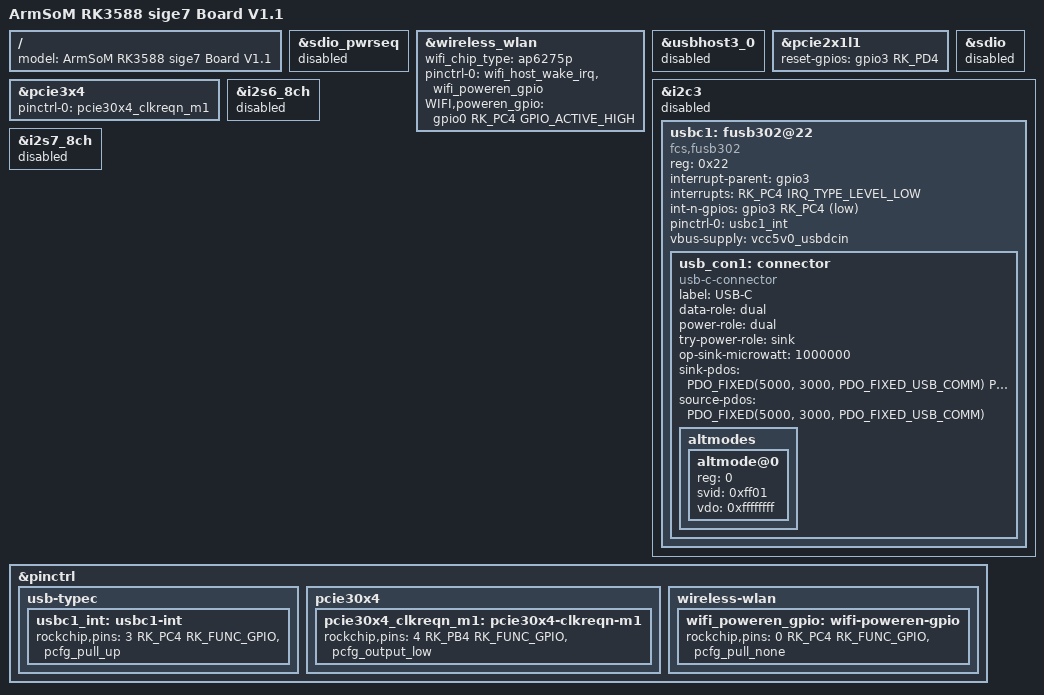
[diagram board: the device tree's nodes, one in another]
/dts-v1/;

#include "rk3588-sige7-v1.dts"

/ {
	model = "ArmSoM RK3588 sige7 Board V1.1";
};

&sdio_pwrseq {
	status = "disabled";
};

&wireless_wlan {
	wifi_chip_type = "ap6275p";
	pinctrl-0 = <&wifi_host_wake_irq>, <&wifi_poweren_gpio>;
	WIFI,poweren_gpio = <&gpio0 RK_PC4 GPIO_ACTIVE_HIGH>;
};

// combphy2_psu mux to pcie2x1l1
&usbhost3_0 {
	status = "disabled";
};

&pcie2x1l1 {
	reset-gpios = <&gpio3 RK_PD4 GPIO_ACTIVE_HIGH>;
	status = "okay";
};

&pcie3x4 {
	pinctrl-names = "default";
	pinctrl-0 = <&pcie30x4_clkreqn_m1>;
};

&sdio {
	status = "disabled";
};

&i2c3 {
	status = "disabled";
	usbc1: fusb302@22 {
		compatible = "fcs,fusb302";
		reg = <0x22>;
		interrupt-parent = <&gpio3>;
		interrupts = <RK_PC4 IRQ_TYPE_LEVEL_LOW>;
		int-n-gpios = <&gpio3 RK_PC4 GPIO_ACTIVE_LOW>;
		pinctrl-names = "default";
		pinctrl-0 = <&usbc1_int>;
		//vbus-supply = <&vcc12v_dcin>;
		vbus-supply = <&vcc5v0_usbdcin>;
		status = "okay";
		usb_con1: connector {
			compatible = "usb-c-connector";
			label = "USB-C";
			data-role = "dual";
			power-role = "dual";
			try-power-role = "sink";
			op-sink-microwatt = <1000000>;
			sink-pdos =
				<PDO_FIXED(5000, 3000, PDO_FIXED_USB_COMM)
				PDO_FIXED(9000, 3000, PDO_FIXED_USB_COMM)
				PDO_FIXED(12000, 3000, PDO_FIXED_USB_COMM)>;
			source-pdos =
				<PDO_FIXED(5000, 3000, PDO_FIXED_USB_COMM)>;

			altmodes {
				#address-cells = <1>;
				#size-cells = <0>;

				altmode@0 {
					reg = <0>;
					svid = <0xff01>;
					vdo = <0xffffffff>;
				};
			};
		};
	};
};

// hdmi1 sound
&i2s6_8ch {
	status = "disabled";
};

// hdmiin sound
&i2s7_8ch {
	status = "disabled";
};

&pinctrl {
	usb-typec {
		usbc1_int: usbc1-int {
			rockchip,pins = <3 RK_PC4 RK_FUNC_GPIO &pcfg_pull_up>;
		};
	};

	pcie30x4 {
		pcie30x4_clkreqn_m1: pcie30x4-clkreqn-m1 {
			rockchip,pins = <4 RK_PB4 RK_FUNC_GPIO &pcfg_output_low>;
		};
	};

	wireless-wlan {
		wifi_poweren_gpio: wifi-poweren-gpio {
			rockchip,pins = <0 RK_PC4 RK_FUNC_GPIO &pcfg_pull_none>;
		};
	};
};
